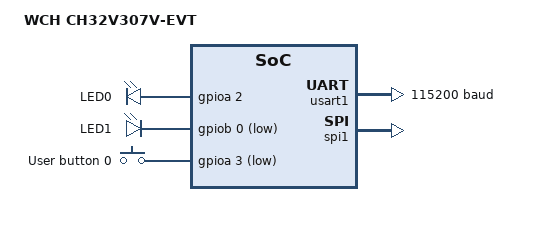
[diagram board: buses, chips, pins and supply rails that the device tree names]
/*
 * Copyright (c) 2021, TODO
 * SPDX-License-Identifier: Apache-2.0
 */

 /dts-v1/;

#include <wch/ch32v307.dtsi>
#include <zephyr/dt-bindings/input/input-event-codes.h>
#include "ch32v307v_evt-pinctrl.dtsi"
 / {
	model = "WCH CH32V307V-EVT";
	compatible = "wch,ch32v307v-evt";

	chosen {
		zephyr,sram = &sram0;
		zephyr,console = &usart1;
		zephyr,shell-uart = &usart1;
		zephyr,flash = &flash0;
	};

	leds {
		compatible = "gpio-leds";
		
		led0: led0 {
			gpios = <&gpioa 2 GPIO_ACTIVE_HIGH>;
			label = "LED0";
		};

		led1: led1 {
			gpios = <&gpiob 0 GPIO_ACTIVE_LOW>;
			label = "LED1";
		};
	};

	buttons {
		compatible = "gpio-keys";
		debounce-interval-ms = <100>;
		user_button_0: button_0 {
			label = "User button 0";
			gpios = <&gpioa 3 (GPIO_PULL_UP | GPIO_ACTIVE_LOW)>;
			zephyr,code = <INPUT_KEY_0>;
		};
	};

	aliases {
		led0 = &led0;
		led1 = &led1;
		sw0 = &user_button_0;
	};

};

&clk_hse {
	status = "okay";
};

&pll1 {
	status = "okay";
};

&rcc {
	clock-frequency = <DT_FREQ_M(144)>;
	apb1-prescaler = <2>;
	apb2-prescaler = <2>;
	clocks = <&pll1>;
};


&usart1 {
	pinctrl-0 = <&usart1_default>;
    pinctrl-names = "default";
	current-speed = <115200>;
	status = "okay";
};

&spi1{
	pinctrl-0 = <&spi1_default>;
	pinctrl-names = "default";
	status = "okay";
};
